# R7FA6M3AH register map
Vendor: Renesas; Series: RA6; File version: 1.2
CPU: CM4 r0p1, little endian, MPU, FPU, VTOR, 4 interrupt priority bits
Registers are 32-bit, read-write, reset 0x0 unless marked. A register's access mark holds for its fields unless they carry their own. Offsets are from the block's base; [hi:lo] are bit positions; {n}, {i} and the like mark numbered series; 'fields as' and 'values as' point back to an identical list.

## EPTPC_CFG — EPTPC Configulation
Base 0x40064500
0x00 PTRSTR — EPTPC Reset Register
  [0] RESET — EPTPC Software Reset
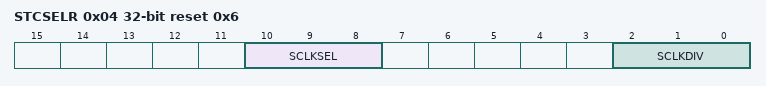
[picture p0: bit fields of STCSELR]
0x04 STCSELR reset 0x6 — STCA Clock Select Register
  [10:8] SCLKSEL — STCA Clock Select
  [2:0] SCLKDIV — PCLKA Clock Frequency Division
0x08 BYPASS — Bypass 1588 module Register
  [0] BYPASS0 — Bypass 1588 module for Ether 0ch

## CRC — CRC Calculator
Base 0x40074000
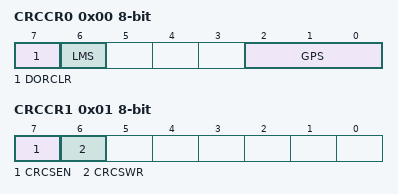
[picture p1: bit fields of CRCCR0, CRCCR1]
0x00 CRCCR0 8-bit — CRC Control Register0
  [7] DORCLR wo — CRCDOR Register Clear
  [6] LMS — CRC Calculation Switching
  [2:0] GPS — CRC Generating Polynomial Switching
0x01 CRCCR1 8-bit — CRC Control Register1
  [7] CRCSEN — Snoop enable bit
  [6] CRCSWR — Snoop,on,write/read switch bit
0x04 CRCDIR — CRC Data Input Register
  [31:0] CRCDIR — Calculation input Data (Case of CRC-32, CRC-32C )
0x04 CRCDIR_BY 8-bit (alternate view of CRCDIR) — CRC Data Input Register (byte access)
  [7:0] CRCDIR_BY — Calculation input Data ( Case of CRC-8, CRC-16 or CRC,CCITT )
0x08 CRCDOR — CRC Data Output Register
  [31:0] CRCDOR — Calculation output Data (Case of CRC-32, CRC-32C )
0x08 CRCDOR_HA 16-bit (alternate view of CRCDOR) — CRC Data Output Register (halfword access)
  [15:0] CRCDOR_HA — Calculation output Data (Case of CRC-16 or CRC,CCITT )
0x08 CRCDOR_BY 8-bit (alternate view of CRCDOR) — CRC Data Output Register(byte access)
  [7:0] CRCDOR_BY — Calculation output Data (Case of CRC-8 )
0x0C CRCSAR 16-bit — Snoop Address Register
  [13:0] CRCSA — snoop address bitSet the I/O register address to snoop

## MMPU — Bus Master MPU
Base 0x40000000
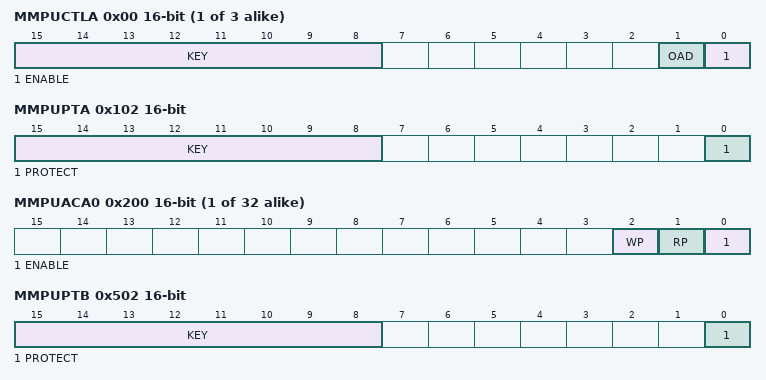
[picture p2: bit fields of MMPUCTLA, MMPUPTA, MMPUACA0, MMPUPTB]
0x00 MMPUCTL{x} (x=A,B,C; step 0x400) 16-bit — Bus Master MPU Control Register
  [15:8] KEY wo — Write Keyword The data written to these bits are not stored.
  [1] OAD — Operation after detection
  [0] ENABLE — Master Group enable
0x102 MMPUPTA 16-bit — Group A Protection of Register
  [15:8] KEY wo — Write Keyword The data written to these bits are not stored.
  [0] PROTECT — Protection of register(MMPUSAn, MMPUEAn and MMPUACAn)
{0x200+0x10*i} MMPUACA{i} (i=0..31) 16-bit — Group A Region {i} Access Control Register
  [2] WP — Write protection
  [1] RP — Read protection
  [0] ENABLE — Region enable
{0x204+0x10*i} MMPUSA{i} (i=0..31) (reset mask 0x3) — Group A Region {i} Start Address Register
  [31:0] MMPUSA — Address where the region starts, for use in region determination.NOTE: The low,order 2 bits are fixed to 0.
{0x208+0x10*i} MMPUEA{i} (i=0..31) reset 0x3 (reset mask 0x3) — Group A Region {i} End Address Register
  [31:0] MMPUEA — Region end address registerAddress where the region end, for use in region determination.NOTE: The low,order 2 bits are fixed to 1.
0x502 MMPUPTB 16-bit — Group B Protection of Register
  [15:8] KEY wo — Write Keyword The data written to these bits are not stored.
  [0] PROTECT — Protection of register(MMPUSBn, MMPUEBn and MMPUACBn)
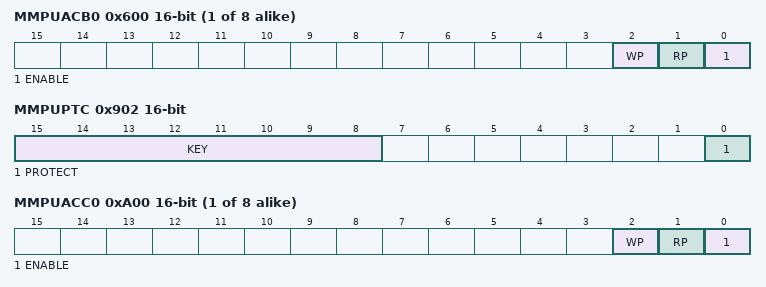
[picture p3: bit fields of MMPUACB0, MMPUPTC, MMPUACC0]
{0x600+0x10*i} MMPUACB{i} (i=0..7) 16-bit — Group B Region {i} Access Control Register
  fields as MMPUACA0
{0x604+0x10*i} MMPUSB{i} (i=0..7) (reset mask 0x3) — Group B Region {i} Start Address Register
  [31:0] MMPUSB — Address where the region starts, for use in region determination.NOTE: The low,order 2 bits are fixed to 0.
{0x608+0x10*i} MMPUEB{i} (i=0..7) reset 0x3 (reset mask 0x3) — Group B Region {i} End Address Register
  [31:0] MMPUEB — Region end address registerAddress where the region end, for use in region determination.NOTE: The low,order 2 bits are fixed to 1.
0x902 MMPUPTC 16-bit — Group C protection of register
  [15:8] KEY wo — Write Keyword The data written to these bits are not stored.
  [0] PROTECT — Protection of register (MMPUSCn, MMPUECn and MMPUACCn)
{0xA00+0x10*i} MMPUACC{i} (i=0..7) 16-bit — Group C Region {i} Access Control Register
  fields as MMPUACA0
{0xA04+0x10*i} MMPUSC{i} (i=0..7) (reset mask 0x3) — Group C Region {i} Start Address Register
  [31:0] MMPUSC — Address where the region starts, for use in region determination.NOTE: The low,order 2 bits are fixed to 0.
{0xA08+0x10*i} MMPUEC{i} (i=0..7) reset 0x3 (reset mask 0x3) — Group C Region {i} End Address Register
  [31:0] MMPUEC — Region end address registerAddress where the region end, for use in region determination.NOTE: The low,order 2 bits are fixed to 1.
